# LPC12D27 register map
File version: 3
Registers are 32-bit, read-write, reset 0x0 unless marked. A register's access mark holds for its fields unless they carry their own. Offsets are from the block's base; [hi:lo] are bit positions.

## WWDT — Product name title=UM10441 Chapter title=LPC122x Windowed Watchdog Timer (WWDT) Modification date=2/2/2011 Major revision=0 Minor revision=17
Base 0x40004000
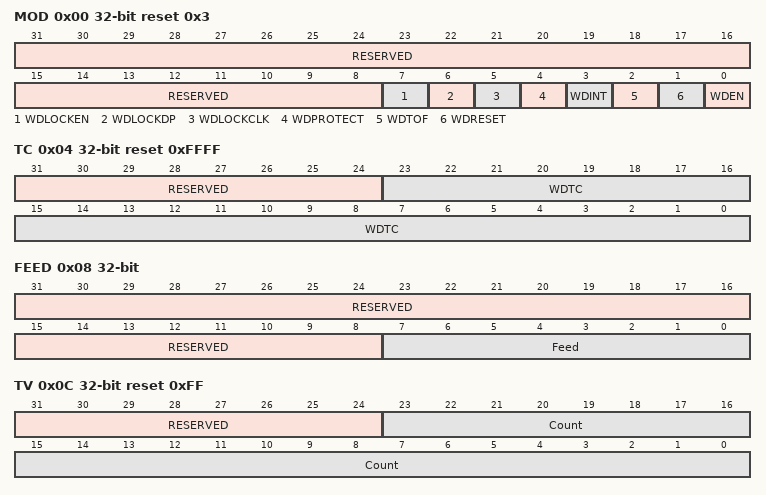
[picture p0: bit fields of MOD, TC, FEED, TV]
0x00 MOD reset 0x3 — Watchdog mode register. This register contains the basic mode and status of the Watchdog Timer.
  [31:8] RESERVED — Reserved, user software should not write ones to reserved bits. The value read from a reserved bit is not defined.
  [7] WDLOCKEN — Watchdog enable and reset lockout bit. This bit is cleared on reset and can subsequently be written to only once to set it. Once this bit has been set, it can only be cleared through resetting the chip.
    0=UNLOCK (The WDEN and WDRESET bits can be written to by software any time to enable or disable watchdog operation.); 1=LOCK (If this bit is set to one, all subsequent writes to the WDEN and WDRESET bits will be blocked. The watchdog will be permanently disabled or enabled depending on the state of the WDEN bit when the WDLOCK bit was set. The reset behavior is affected as follows: If the watchdog is enabled and the WDRESET is bit set to one before setting the WDLOCKEN bit, a watchdog trigger always causes a reset and this behavior cannot be overwritten by software. If the watchdog is enabled and the WDRESET bit is set to zero before setting the WDLOCKEN bit, a watchdog trigger always causes an interrupt and this behavior cannot be overwritten by software.)
  [6] WDLOCKDP — Deep power-down disable bit. This bit is cleared on reset and can subsequently be written to only once to set it. Once this bit has been set, it can only be cleared through resetting the chip.
    0=DPDEN_UNLOCK (Deep power-down mode can be entered at any time.); 1=DPDEN_LOCK (The DPDEN bit in the PMU (see Table 54 Power control register (PCON, address 0x4003 8000) bit description) cannot be set to 1.)
  [5] WDLOCKCLK — Watchdog clock lock bit. This bit is cleared on reset and can subsequently be written to only once to set it. Once this bit has been set, it can only be cleared through resetting the chip.
    0=THE_WATCHDOG_CLOCK_( (The watchdog clock (WDCLK) can be disabled at any time.); 1=SETTING_THIS_BIT_DIS (Setting this bit disables any writes to the bit or bits that control the power to the currently selected watchdog clock source in the power configuration registers PDRUNCFG, PDSLEEPCFG, and PDAWAKECFG. Other bits in the power configuration registers are not affected. Setting the WDLOCKCLK bit ensures that the WDT always has a valid clock source for WDCLK provided that the watchdog oscillator and/or the IRC are powered. Before setting the WDLOCKCLK bit, the user must enable either the watchdog oscillator or the IRC or both in all three power configuration registers in order to keep the selected clock source running in Active, Sleep, or Deep-sleep modes. Once the WDLOCKCLK bit is set, the watchdog clock source cannot be switched off or on. If the WDT is to be running in Deep-sleep mode, the watchdog oscillator must be enabled in the PDSLEEPCFG register before setting the WDLOCKCLK bit .)
  [4] WDPROTECT — Watchdog update mode. This bit is Set Only. Once the WDPROTECT bit is set it can not be cleared by software. The WDPROTECT bit is cleared by an external reset or a Watchdog timer reset.
    0=UNLOCK (The watchdog timer constant value (WDTC) can be changed at any time.); 1=LOCK (The watchdog timer constant value (WDTC) can be changed only after the counter is below the value of WARNINT and WINDOW.)
  [3] WDINT — The Watchdog interrupt flag is set when the Watchdog counter reaches the value specified by WDWARNINT. This flag is cleared when any reset occurs, and is cleared by software by writing a 1 to this bit.
  [2] WDTOF — Watchdog time-out flag. The Watchdog time-out flag is set when the Watchdog times out, when a feed error occurs, or when WDPROTECT =1 and an attempt is made to write to the WDTC register. This flag is cleared by software writing a 0 to this bit. Causes a chip reset if WDRESET = 1.
  [1] WDRESET — Watchdog reset enable bit. This bit can be changed at any time. The WDRESET bit is set by an external reset or a Watchdog timer reset. The WDRESET bit can be locked from subsequent writes by the WDLOCKEN bit.
    0=INTERRUPT (A watchdog time-out will cause an interrupt.); 1=RESET (A watchdog timeout will cause a chip reset.)
  [0] WDEN — Watchdog enable bit. The WDEN bit can be locked from subsequent writes by the WDLOCKEN bit.
    0=STOPPED (The watchdog timer is stopped.); 1=RUNNING (The watchdog timer is running. The watchdog timer is automatically enabled at reset without requiring a valid feed sequence. Any subsequent writes to this bit require a valid feed sequence before the change can take effect.)
0x04 TC reset 0xFFFF — Watchdog timer constant register. This register determines the time-out value.
  [31:24] RESERVED — Reserved, user software should not write ones to reserved bits. The value read from a reserved bit is not defined.
  [23:0] WDTC — Watchdog time-out interval.
0x08 FEED wo — Watchdog feed sequence register. Writing 0xAA followed by 0x55 to this register reloads the Watchdog timer with the value contained in TC.
  [31:8] RESERVED — Reserved, user software should not write ones to reserved bits. The value read from a reserved bit is not defined.
  [7:0] Feed — Feed value should be 0xAA followed by 0x55.
0x0C TV ro reset 0xFF — Watchdog timer value register. This register reads out the current value of the Watchdog timer.
  [31:24] RESERVED — Reserved, user software should not write ones to reserved bits. The value read from a reserved bit is not defined.
  [23:0] Count — Counter timer value.
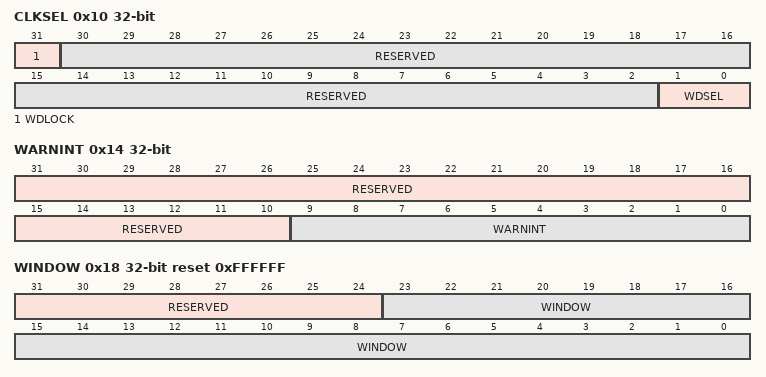
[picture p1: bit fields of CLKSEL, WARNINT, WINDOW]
0x10 CLKSEL — Watchdog clock source selection register.
  [31] WDLOCK — Lock Watchdog clock source.
    0=LOCK (This bit is set to 0 on any reset. It cannot be cleared by software.); 1=UNLOCK (Software can set this bit to 1 at any time. Once WDLOCK is set, the bits of this register cannot be modified.)
  [30:2] RESERVED — Reserved, user software should not write ones to reserved bits. The value read from a reserved bit is not defined.
  [1:0] WDSEL — These bits select the clock source for the Watchdog timer as described below. Warning: Improper setting of this value may result in incorrect operation of the Watchdog timer, which could adversely affect system operation. If the WDLOCK bit in this register is set, the WDSEL bits cannot be modified. Writes to the WDSEL bits are ignored if the corresponding clock source is powered down in the PDRUNCFG register (Table 49).
    0=IRC (Selects the Internal RC oscillator as the Watchdog clock source (default). In active mode only.); 1=WDOSC (Selects the watchdog oscillator as the Watchdog clock source. Must be selected if the WDT is running in Deep-sleep mode.); 2=RESERVED_DO_NOT_USE; 3=RESERVED_DO_NOT_USE
0x14 WARNINT — Watchdog Warning Interrupt compare value.
  [31:10] RESERVED — Reserved, user software should not write ones to reserved bits. The value read from a reserved bit is not defined.
  [9:0] WARNINT — Watchdog warning interrupt compare value.
0x18 WINDOW reset 0xFFFFFF — Watchdog Window compare value.
  [31:24] RESERVED — Reserved, user software should not write ones to reserved bits. The value read from a reserved bit is not defined.
  [23:0] WINDOW — Watchdog window value.
